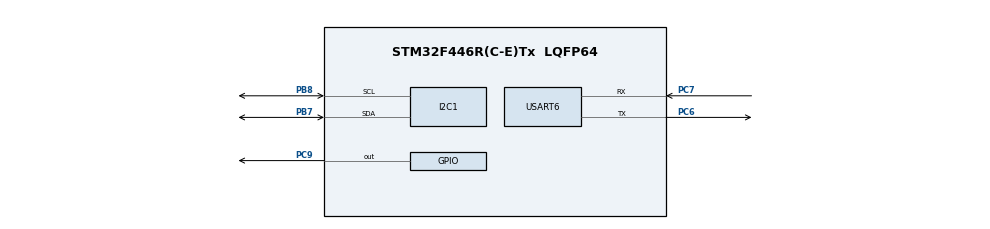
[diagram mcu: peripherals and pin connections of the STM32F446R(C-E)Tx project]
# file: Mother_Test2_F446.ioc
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Mcu.Family=STM32F4
Mcu.Name=STM32F446R(C-E)Tx
Mcu.Package=LQFP64
NVIC.PriorityGroup=NVIC_PRIORITYGROUP_4
PB7.Mode=I2C
PB7.Signal=I2C1_SDA
PB8.Mode=I2C
PB8.Signal=I2C1_SCL
PC6.Mode=Asynchronous
PC6.Signal=USART6_TX
PC7.Mode=Asynchronous
PC7.Signal=USART6_RX
PC9.GPIO_PuPd=GPIO_NOPULL
PC9.Signal=GPIO_Output
ProjectManager.HeapSize=0x200
ProjectManager.StackSize=0x400
ProjectManager.TargetToolchain=STM32CubeIDE
RCC.CortexFreq_Value=16000000
RCC.USBFreq_Value=96000000
RCC.VCOOutputFreq_Value=192000000
USART6.VirtualMode=VM_ASYNC
board=custom

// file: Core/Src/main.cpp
/* USER CODE BEGIN Header */
/**
  ******************************************************************************
  * @file           : main.c
  * @brief          : Main program body
  ******************************************************************************
  * @attention
  *
  * Copyright (c) 2024 STMicroelectronics.
  * All rights reserved.
  *
  * This software is licensed under terms that can be found in the LICENSE file
  * in the root directory of this software component.
  * If no LICENSE file comes with this software, it is provided AS-IS.
  *
  ******************************************************************************
  */
/* USER CODE END Header */
#include "main.h"

/* USER CODE BEGIN Includes */
#include "bno055_stm32.h"
#include "move.h"

/* USER CODE END Includes */

I2C_HandleTypeDef hi2c1;

UART_HandleTypeDef huart6;

/* USER CODE BEGIN PV */
int rotate;

/* USER CODE END PV */

void SystemClock_Config(void);
static void MX_GPIO_Init(void);
static void MX_I2C1_Init(void);
static void MX_USART6_UART_Init(void);

int main(void)
{

  /* MCU Configuration--------------------------------------------------------*/

  /* Reset of all peripherals, Initializes the Flash interface and the Systick. */
  HAL_Init();

  /* Configure the system clock */
  SystemClock_Config();

  /* Initialize all configured peripherals */
  MX_GPIO_Init();
  MX_I2C1_Init();
  MX_USART6_UART_Init();
  /* USER CODE BEGIN 2 */
  bno055_assignI2C(&hi2c1);
  bno055_setup();
  bno055_setOperationModeNDOF();

  /* USER CODE END 2 */

  /* Infinite loop */
  while (1)
  {

    /* USER CODE BEGIN 3 */
	  bno055_vector_t v = bno055_getVectorQuaternion();
	  rotate = v.w;
	  HAL_Delay(10);
  }
  /* USER CODE END 3 */
}

void SystemClock_Config(void)
{
  RCC_OscInitTypeDef RCC_OscInitStruct = {0};
  RCC_ClkInitTypeDef RCC_ClkInitStruct = {0};

  /** Configure the main internal regulator output voltage
  */
  __HAL_RCC_PWR_CLK_ENABLE();
  __HAL_PWR_VOLTAGESCALING_CONFIG(PWR_REGULATOR_VOLTAGE_SCALE3);

  /** Initializes the RCC Oscillators according to the specified parameters
  * in the RCC_OscInitTypeDef structure.
  */
  RCC_OscInitStruct.OscillatorType = RCC_OSCILLATORTYPE_HSI;
  RCC_OscInitStruct.HSIState = RCC_HSI_ON;
  RCC_OscInitStruct.HSICalibrationValue = RCC_HSICALIBRATION_DEFAULT;
  RCC_OscInitStruct.PLL.PLLState = RCC_PLL_NONE;
  if (HAL_RCC_OscConfig(&RCC_OscInitStruct) != HAL_OK)
  {
    Error_Handler();
  }

  /** Initializes the CPU, AHB and APB buses clocks
  */
  RCC_ClkInitStruct.ClockType = RCC_CLOCKTYPE_HCLK|RCC_CLOCKTYPE_SYSCLK
                              |RCC_CLOCKTYPE_PCLK1|RCC_CLOCKTYPE_PCLK2;
  RCC_ClkInitStruct.SYSCLKSource = RCC_SYSCLKSOURCE_HSI;
  RCC_ClkInitStruct.AHBCLKDivider = RCC_SYSCLK_DIV1;
  RCC_ClkInitStruct.APB1CLKDivider = RCC_HCLK_DIV1;
  RCC_ClkInitStruct.APB2CLKDivider = RCC_HCLK_DIV1;

  if (HAL_RCC_ClockConfig(&RCC_ClkInitStruct, FLASH_LATENCY_0) != HAL_OK)
  {
    Error_Handler();
  }
}

static void MX_I2C1_Init(void)
{

  hi2c1.Instance = I2C1;
  hi2c1.Init.ClockSpeed = 100000;
  hi2c1.Init.DutyCycle = I2C_DUTYCYCLE_2;
  hi2c1.Init.OwnAddress1 = 0;
  hi2c1.Init.AddressingMode = I2C_ADDRESSINGMODE_7BIT;
  hi2c1.Init.DualAddressMode = I2C_DUALADDRESS_DISABLE;
  hi2c1.Init.OwnAddress2 = 0;
  hi2c1.Init.GeneralCallMode = I2C_GENERALCALL_DISABLE;
  hi2c1.Init.NoStretchMode = I2C_NOSTRETCH_DISABLE;
  if (HAL_I2C_Init(&hi2c1) != HAL_OK)
  {
    Error_Handler();
  }

}

static void MX_USART6_UART_Init(void)
{

  huart6.Instance = USART6;
  huart6.Init.BaudRate = 115200;
  huart6.Init.WordLength = UART_WORDLENGTH_8B;
  huart6.Init.StopBits = UART_STOPBITS_1;
  huart6.Init.Parity = UART_PARITY_NONE;
  huart6.Init.Mode = UART_MODE_TX_RX;
  huart6.Init.HwFlowCtl = UART_HWCONTROL_NONE;
  huart6.Init.OverSampling = UART_OVERSAMPLING_16;
  if (HAL_UART_Init(&huart6) != HAL_OK)
  {
    Error_Handler();
  }

}

static void MX_GPIO_Init(void)
{
  GPIO_InitTypeDef GPIO_InitStruct = {0};

  /* GPIO Ports Clock Enable */
  __HAL_RCC_GPIOC_CLK_ENABLE();
  __HAL_RCC_GPIOB_CLK_ENABLE();

  /*Configure GPIO pin Output Level */
  HAL_GPIO_WritePin(GPIOC, GPIO_PIN_9, GPIO_PIN_RESET);

  /*Configure GPIO pin : PC9 */
  GPIO_InitStruct.Pin = GPIO_PIN_9;
  GPIO_InitStruct.Mode = GPIO_MODE_OUTPUT_PP;
  GPIO_InitStruct.Pull = GPIO_NOPULL;
  GPIO_InitStruct.Speed = GPIO_SPEED_FREQ_LOW;
  HAL_GPIO_Init(GPIOC, &GPIO_InitStruct);

}

void Error_Handler(void)
{
  __disable_irq();
  while (1)
  {
  }
}
